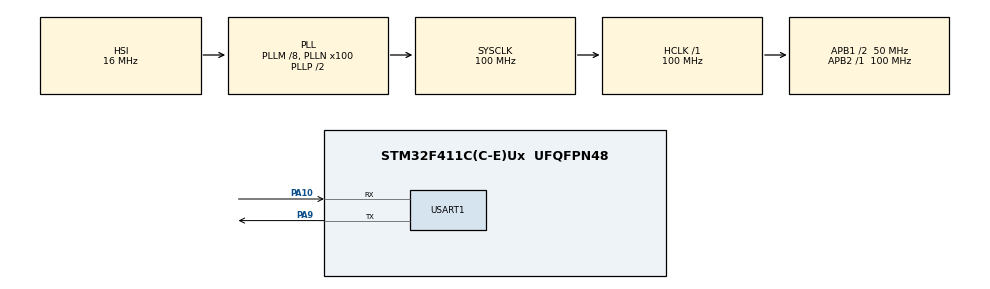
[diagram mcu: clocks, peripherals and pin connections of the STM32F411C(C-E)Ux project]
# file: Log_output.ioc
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Mcu.Family=STM32F4
Mcu.Name=STM32F411C(C-E)Ux
Mcu.Package=UFQFPN48
NVIC.PriorityGroup=NVIC_PRIORITYGROUP_4
PA10.Mode=Asynchronous
PA10.Signal=USART1_RX
PA13.Mode=Serial_Wire
PA13.Signal=SYS_JTMS-SWDIO
PA14.Mode=Serial_Wire
PA14.Signal=SYS_JTCK-SWCLK
PA9.Mode=Asynchronous
PA9.Signal=USART1_TX
PC14-OSC32_IN.Mode=LSE-External-Oscillator
PC14-OSC32_IN.Signal=RCC_OSC32_IN
PC15-OSC32_OUT.Mode=LSE-External-Oscillator
PC15-OSC32_OUT.Signal=RCC_OSC32_OUT
PH0\ -\ OSC_IN.Mode=HSE-External-Oscillator
PH0\ -\ OSC_IN.Signal=RCC_OSC_IN
PH1\ -\ OSC_OUT.Mode=HSE-External-Oscillator
PH1\ -\ OSC_OUT.Signal=RCC_OSC_OUT
ProjectManager.HeapSize=0x200
ProjectManager.StackSize=0x400
ProjectManager.TargetToolchain=MDK-ARM V5.32
RCC.48MHZClocksFreq_Value=50000000
RCC.AHBFreq_Value=100000000
RCC.APB1CLKDivider=RCC_HCLK_DIV2
RCC.APB1Freq_Value=50000000
RCC.APB1TimFreq_Value=100000000
RCC.APB2Freq_Value=100000000
RCC.APB2TimFreq_Value=100000000
RCC.CortexFreq_Value=100000000
RCC.HCLKFreq_Value=100000000
RCC.HSE_VALUE=25000000
RCC.HSI_VALUE=16000000
RCC.PLLM=8
RCC.PLLN=100
RCC.RCC_RTC_Clock_Source=RCC_RTCCLKSOURCE_LSE
RCC.SYSCLKFreq_VALUE=100000000
RCC.SYSCLKSource=RCC_SYSCLKSOURCE_PLLCLK
RCC.VCOOutputFreq_Value=200000000
RTC.Date=8
RTC.Hours=17
RTC.Minutes=30
RTC.Month=RTC_MONTH_JULY
RTC.WeekDay=RTC_WEEKDAY_WEDNESDAY
RTC.Year=26
USART1.VirtualMode=VM_ASYNC
VP_RTC_VS_RTC_Activate.Mode=RTC_Enabled
VP_RTC_VS_RTC_Calendar.Mode=RTC_Calendar
board=custom

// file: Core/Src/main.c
/* USER CODE BEGIN Header */
/**
  ******************************************************************************
  * @file           : main.c
  * @brief          : Main program body
  ******************************************************************************
  * @attention
  *
  * Copyright (c) 2026 STMicroelectronics.
  * All rights reserved.
  *
  * This software is licensed under terms that can be found in the LICENSE file
  * in the root directory of this software component.
  * If no LICENSE file comes with this software, it is provided AS-IS.
  *
  ******************************************************************************
  */
/* USER CODE END Header */
#include "main.h"
#include "rtc.h"
#include "usart.h"
#include "gpio.h"

/* USER CODE BEGIN Includes */
#include <stdio.h>
#include "SEGGER_RTT.h"
#include "elog.h"
/* USER CODE END Includes */

void SystemClock_Config(void);

/* USER CODE BEGIN 0 */
#ifdef __GNUC__
	#define PUTCHAR_PROTOTYPR int _io_putchar(int ch)
#else
	#define PUTCHAR_PROTOTYPR int fputc(int ch, FILE *f)
#endif /* __GNUC__ */

PUTCHAR_PROTOTYPR
{
	HAL_UART_Transmit(&huart1, (uint8_t *) &ch, 1, 0xFFFF);
	return ch;
}

void EasyLogger_Init(void)
{
  // 初始化 elog
	elog_init();
  // 使能文字颜色
  elog_set_text_color_enabled(true);
  // 设置日志格式
	elog_set_fmt(ELOG_LVL_ASSERT, ELOG_FMT_ALL & ~(ELOG_FMT_P_INFO | ELOG_FMT_T_INFO));
	elog_set_fmt(ELOG_LVL_ERROR, ELOG_FMT_ALL& ~(ELOG_FMT_P_INFO | ELOG_FMT_T_INFO));
	elog_set_fmt(ELOG_LVL_WARN, ELOG_FMT_ALL & ~(ELOG_FMT_P_INFO | ELOG_FMT_T_INFO));
	elog_set_fmt(ELOG_LVL_INFO, ELOG_FMT_ALL & ~(ELOG_FMT_P_INFO | ELOG_FMT_T_INFO));
	elog_set_fmt(ELOG_LVL_DEBUG, ELOG_FMT_ALL & ~(ELOG_FMT_P_INFO | ELOG_FMT_T_INFO));
	elog_set_fmt(ELOG_LVL_VERBOSE, ELOG_FMT_ALL & ~(ELOG_FMT_P_INFO | ELOG_FMT_T_INFO));
  // 开启日志
  elog_start();
}

void log_test(void)
{
	log_a("this is a assert log");
	log_e("this is an error log");
	log_w("this is a warning log");
	log_i("this is an info log");
	log_d("this is a debug log");
	log_v("this is a verbose log");
}
/* USER CODE END 0 */

int main(void)
{

  /* MCU Configuration--------------------------------------------------------*/

  /* Reset of all peripherals, Initializes the Flash interface and the Systick. */
  HAL_Init();

  /* Configure the system clock */
  SystemClock_Config();

  /* Initialize all configured peripherals */
  MX_GPIO_Init();
  MX_USART1_UART_Init();
  MX_RTC_Init();
  /* USER CODE BEGIN 2 */
  EasyLogger_Init();
  log_test();
  /* USER CODE END 2 */

  /* Infinite loop */
  while (1)
  {

  }
}

void SystemClock_Config(void)
{
  RCC_OscInitTypeDef RCC_OscInitStruct = {0};
  RCC_ClkInitTypeDef RCC_ClkInitStruct = {0};

  /** Configure the main internal regulator output voltage
  */
  __HAL_RCC_PWR_CLK_ENABLE();
  __HAL_PWR_VOLTAGESCALING_CONFIG(PWR_REGULATOR_VOLTAGE_SCALE1);

  /** Initializes the RCC Oscillators according to the specified parameters
  * in the RCC_OscInitTypeDef structure.
  */
  RCC_OscInitStruct.OscillatorType = RCC_OSCILLATORTYPE_HSI|RCC_OSCILLATORTYPE_LSE;
  RCC_OscInitStruct.LSEState = RCC_LSE_ON;
  RCC_OscInitStruct.HSIState = RCC_HSI_ON;
  RCC_OscInitStruct.HSICalibrationValue = RCC_HSICALIBRATION_DEFAULT;
  RCC_OscInitStruct.PLL.PLLState = RCC_PLL_ON;
  RCC_OscInitStruct.PLL.PLLSource = RCC_PLLSOURCE_HSI;
  RCC_OscInitStruct.PLL.PLLM = 8;
  RCC_OscInitStruct.PLL.PLLN = 100;
  RCC_OscInitStruct.PLL.PLLP = RCC_PLLP_DIV2;
  RCC_OscInitStruct.PLL.PLLQ = 4;
  if (HAL_RCC_OscConfig(&RCC_OscInitStruct) != HAL_OK)
  {
    Error_Handler();
  }

  /** Initializes the CPU, AHB and APB buses clocks
  */
  RCC_ClkInitStruct.ClockType = RCC_CLOCKTYPE_HCLK|RCC_CLOCKTYPE_SYSCLK
                              |RCC_CLOCKTYPE_PCLK1|RCC_CLOCKTYPE_PCLK2;
  RCC_ClkInitStruct.SYSCLKSource = RCC_SYSCLKSOURCE_PLLCLK;
  RCC_ClkInitStruct.AHBCLKDivider = RCC_SYSCLK_DIV1;
  RCC_ClkInitStruct.APB1CLKDivider = RCC_HCLK_DIV2;
  RCC_ClkInitStruct.APB2CLKDivider = RCC_HCLK_DIV1;

  if (HAL_RCC_ClockConfig(&RCC_ClkInitStruct, FLASH_LATENCY_3) != HAL_OK)
  {
    Error_Handler();
  }
}

void Error_Handler(void)
{
  __disable_irq();
  while (1)
  {
  }
}
